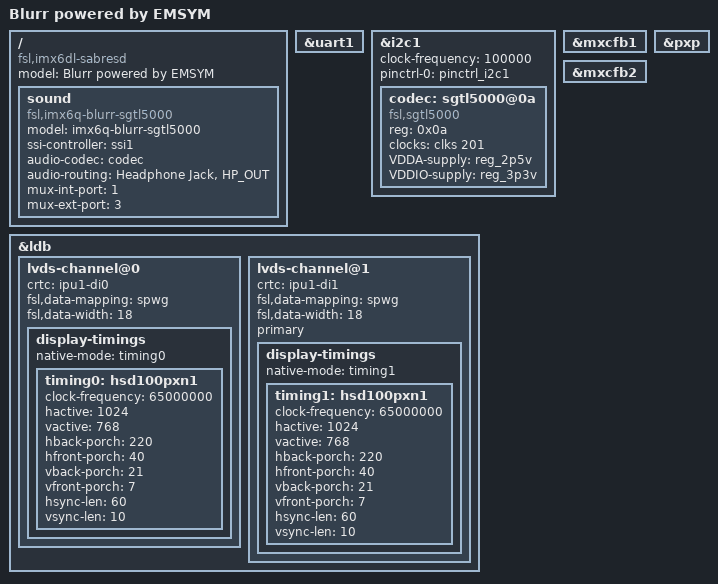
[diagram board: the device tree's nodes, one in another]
/*
 * Copyright (C) 2013-2015 Freescale Semiconductor, Inc.
 *
 * This program is free software; you can redistribute it and/or modify
 * it under the terms of the GNU General Public License version 2 as
 * published by the Free Software Foundation.
 */

/dts-v1/;

#include "imx6dl.dtsi"
#include "imx6qdl-blurr.dtsi"

/ {
	model = "Blurr powered by EMSYM";
	compatible = "fsl,imx6dl-sabresd", "fsl,imx6dl";

        sound {
                compatible = "fsl,imx6q-blurr-sgtl5000",
                             "fsl,imx-audio-sgtl5000";
                model = "imx6q-blurr-sgtl5000";
                ssi-controller = <&ssi1>;
                audio-codec = <&codec>;
                audio-routing = "Headphone Jack", "HP_OUT";
                mux-int-port = <1>;
                mux-ext-port = <3>;
        };

};

&uart1 {
	status = "okay";
};

&i2c1 {
        clock-frequency = <100000>;
        pinctrl-names = "default";
        pinctrl-0 = <&pinctrl_i2c1>;
        status = "okay";

        codec: sgtl5000@0a {
                compatible = "fsl,sgtl5000";
                reg = <0x0a>;
                clocks = <&clks 201>;
                VDDA-supply = <&reg_2p5v>;
                VDDIO-supply = <&reg_3p3v>;
        };

};

&ldb {
	status = "okay";

	lvds-channel@0 {
		crtc = "ipu1-di0";
		fsl,data-mapping = "spwg";
		fsl,data-width = <18>;
		status = "okay";

		display-timings {
                        native-mode = <&timing0>;
                        timing0: hsd100pxn1 {
                                clock-frequency = <65000000>;
                                hactive = <1024>;
                                vactive = <768>;
                                hback-porch = <220>;
                                hfront-porch = <40>;
                                vback-porch = <21>;
                                vfront-porch = <7>;
                                hsync-len = <60>;
                                vsync-len = <10>;
                        };
                };
	};

	lvds-channel@1 {
		crtc = "ipu1-di1";
		fsl,data-mapping = "spwg";
		fsl,data-width = <18>;
		primary; 
		status = "okay";

		display-timings {
                        native-mode = <&timing1>;
                        timing1: hsd100pxn1 {
                                clock-frequency = <65000000>;
                                hactive = <1024>;
                                vactive = <768>;
                                hback-porch = <220>;
                                hfront-porch = <40>;
                                vback-porch = <21>;
                                vfront-porch = <7>;
                                hsync-len = <60>;
                                vsync-len = <10>;
                        };
                };
	};
};

&mxcfb1 {
	status = "okay";
};

&mxcfb2 {
	status = "okay";
};

&pxp {
	status = "okay";
};
